# A33M11x register map
Vendor: ABOV Semiconductor Co., Ltd.; File version: 1.0
CPU: CM3 r0p1, little endian, MPU, FPU, VTOR, 4 interrupt priority bits
Registers are 32-bit, read-write, reset 0x0 unless marked. A register's access mark holds for its fields unless they carry their own. Offsets are from the block's base; [hi:lo] are bit positions; {n}, {i} and the like mark numbered series.

## DMA0 — Direct Memory Access Control
Base 0x40000400
Same registers: DMA1 0x40000410, DMA2 0x40000420, DMA3 0x40000430, DMA4 0x40000440, DMA5 0x40000450, DMA6 0x40000460, DMA7 0x40000470
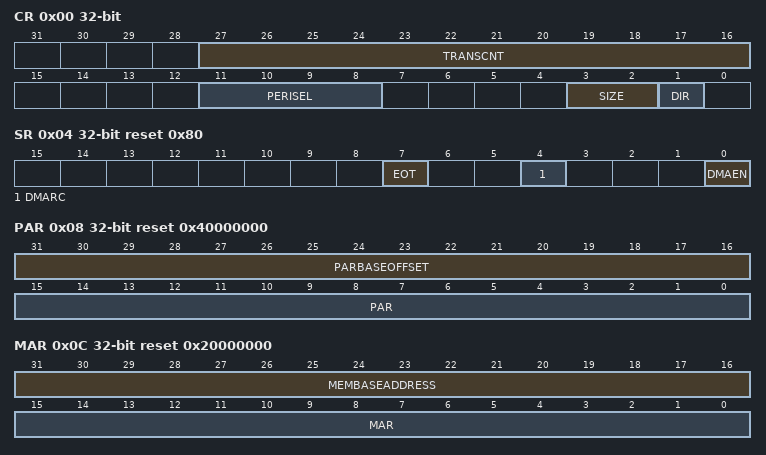
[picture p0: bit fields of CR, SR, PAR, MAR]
0x00 CR — DMA Control Register
  [27:16] TRANSCNT — DMA Transmit counter
  [11:8] PERISEL — Peripheral Selection Bit
  [3:2] SIZE — Bus Transmit Size
    0=Byte (transmit byte size); 1=half_word (transmit half word size); 2=word (transmit word size)
  [1] DIR — Transmit direction selection bit
    0=MEM_TO_PERI (Memory->Peripheral); 1=PERI_TO_MEM (Peripheral->Memory)
0x04 SR reset 0x80 — DMA Status Register
  [7] EOT ro — Transmit is over
  [4] DMARC — DMA Request Clear Bit(Auto Clear)
  [0] DMAEN — DMA Enable Bit
0x08 PAR reset 0x40000000 — DMA Peripheral address register
  [31:16] PARBASEOFFSET ro — Peripheral Base Offset
  [15:0] PAR — Peripheral address bit
0x0C MAR reset 0x20000000 — DMA Memory address register
  [31:16] MEMBASEADDRESS ro — Memory Base Address
  [15:0] MAR — Purpose Memory Address

## WDT — WATCH-DOG TIMER
Base 0x40000200
0x00 LR — Watch-dog Timer Load Register
  [31:0] WDTLR — WDT Load Value Bits
0x04 CNT reset 0x7A12 — Watch-dog Timer Counter Register
  [31:0] WDTCNT ro — Watch-dog Timer Counter Value Bits
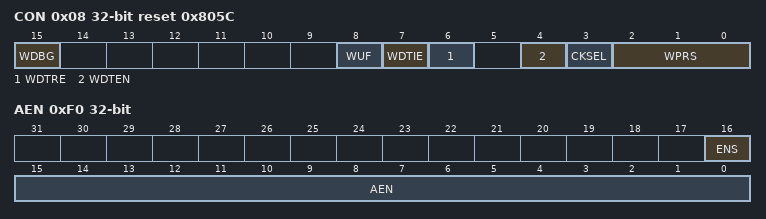
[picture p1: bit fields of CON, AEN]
0x08 CON reset 0x805C — Watch-dog Timer Control Register
  [15] WDBG — Watch-dog Timer Control in debugging mode
  [8] WUF — Watch-dog Timer Underflow Flag Bit, when write WDTLR register, this bit is cleared.
  [7] WDTIE — Watch-dog Timer Underflow Interrupt Enable bit
  [6] WDTRE — Watch-dog Timer Underflow Reset Enable bit
  [4] WDTEN — Watch-dog Timer Counter Enable bit
  [3] CKSEL — Watch-dog Timer Clock Source Selection Bit
  [2:0] WPRS — Watch-dog Timer Counter Clock Prescaler bit
    0=WDTCLKIN_DIV_BY_1 (WDT Input Clock divide by 1); 1=WDTCLKIN_DIV_BY_4 (WDT Input Clock divide by 4); 2=WDTCLKIN_DIV_BY_8 (WDT Input Clock divide by 8); 3=WDTCLKIN_DIV_BY_16 (WDT Input Clock divide by 16); 4=WDTCLKIN_DIV_BY_32 (WDT Input Clock divide by 32); 5=WDTCLKIN_DIV_BY_64 (WDT Input Clock divide by 64); 6=WDTCLKIN_DIV_BY_128 (WDT Input Clock divide by 128); 7=WDTCLKIN_DIV_BY_256 (WDT Input Clock divide by 256)
0xF0 AEN — Watch-dog Timer Master Lock/Reload Register
  [16] ENS ro — Enable status bit
  [15:0] AEN wo — WDT Master Lock Enable Register (Access = 0xA55A, Reload = 0x555A)

## TIMER0 — TIMER COUNTER 0
Base 0x40003000
Same registers: TIMER1 0x40003040, TIMER2 0x40003080, TIMER3 0x400030C0, TIMER4 0x40003100, TIMER5 0x40003140, TIMER6 0x40003180, TIMER7 0x400031C0
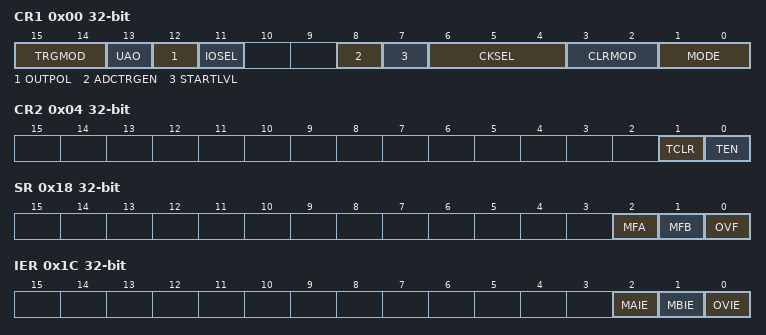
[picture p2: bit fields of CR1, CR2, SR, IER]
0x00 CR1 — Timer Control Register1
  [15:14] TRGMOD — Timer ADC Trigger Mode Selection Bit
    0=GRA (GRA Value Trigger Mode (Normal Mode)); 2=TRGPNT (TRGPNT Value Trigger Mode); 3=GRA_TRGPNT (GRA, TRGPNT Value Both Trigger Mode)
  [13] UAO — GRA, GRB Update Mode Selection bit
    0=Next_Period (Write Value Apply to next period); 1=Current_Period (Write value apply to current period)
  [12] OUTPOL — TIMER Output Polarity Selection Bit
    0=Normal Output; 1=Polarity (Polairty Output)
  [11] IOSEL — TIMER Input/Output Selection Bit
    0=Input (Timer Input Port Setting); 1=Output (Timer Output Port Setting)
  [8] ADCTRGEN — ADC Trigger Source Enable Bit
    0=NoUsed; 1=Used
  [7] STARTLVL — Interval/PWM/One-shot Mode Initial output value setting
    0=Low (Output Start Low); 1=High (Output Start High)
  [6:4] CKSEL — Timer Clock Source Selection bit
    0=PCLK_DIV2 (Counter Clock is PCLK/2); 1=PCLK_DIV4 (Counter Clock is PCLK/4); 2=PCLK_DIV16 (Counter Clock is PCLK/16); 3=PCLK_DIV64 (Counter Clock is PCLK/64); 4=EXT0_MCCR3 (Counter Clock is EXT0(MCCR3)); 6=TnC (Counter Clock is TnC (input pin))
  [3:2] CLRMOD — Capture Mode Clear Selection bit
    0=Rising Edge Clear Mode; 1=Falling Edge Clear Mode; 2=Both (Rising/Falling Edge Clear Mode); 3=Not Clear Mode
  [1:0] MODE — TIMER Operating Mode Control Bit
    0=Interval (Timer is Interval Mode); 1=PWM (Timer is PWM Mode); 2=Oneshot (Timer is One-Shot Mode); 3=Capture (Timer is Capture Mode)
0x04 CR2 — Timer Control Register2
  [1] TCLR wo — Timer Counter Register Clear Bit
  [0] TEN — Timer Counter
    0=Disable (Timer Disable); 1=Enable (Timer Enable)
0x08 PRS — Timer Prescaler Register
  [9:0] PRS — Counter Clock Prescaler Value, TCLK=CLOCK_IN/(PRS+1)
0x0C GRA — Timer General Data Register A
  [15:0] GRA — GRA Value Bit
0x10 GRB — Timer General Data Register B
  [15:0] GRB — GRB Balue Bit
0x14 CNT — Timer Counter Register
  [15:0] CNT — Timer Counter bits.
0x18 SR — Timer Status Register
  [2] MFA — GRA Match Flag
  [1] MFB — GRB Match Flag
  [0] OVF — Counter Overflow Flag
0x1C IER — Timer Interrupt Enable Register
  [2] MAIE — GRA Match Interrupt Enable bit
  [1] MBIE — GRB Match Interrupt Enable bit
  [0] OVIE — Counter Overflow Interrupt Enable bit
0x20 TRGPNT — Timer Trigger Point Register
  [15:0] TRGPNT — Timer Trigger Point Value Bit
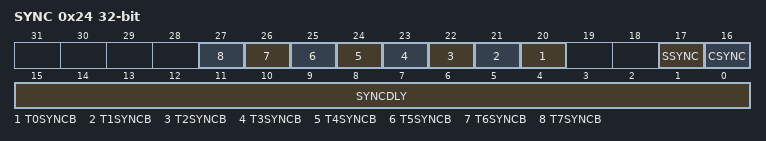
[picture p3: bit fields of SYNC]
0x24 SYNC — Timer Sync Setting Register
  [n+20] T{n}SYNCB (n=0..7) — Timer {n} sync enable bit
    0=Disable (SYNC Disable); 1=Enable (SYNC Enable)
  [17] SSYNC — Timer n Counter Start Sync
    0=Disable (SYNC Disable); 1=Enable (SYNC Enable)
  [16] CSYNC — Timer n Counter Clear Sync
    0=Disable (SYNC Disable); 1=Enable (SYNC Enable)
  [15:0] SYNCDLY — SYNC Delay Counter Value Setting Bit
